# iND83213A register map
Vendor: Indiemicro; Series: Rugby; File version: 1.0
CPU: CM0 r0p1, selectable endian, no MPU, no FPU, 4 interrupt priority bits
Registers are 32-bit, read-write, no defined reset value unless marked. A register's access mark holds for its fields unless they carry their own. Offsets are from the block's base; [hi:lo] are bit positions.

## UART — UART Interface registers
Base 0x50010800; register names take the prefix UART_
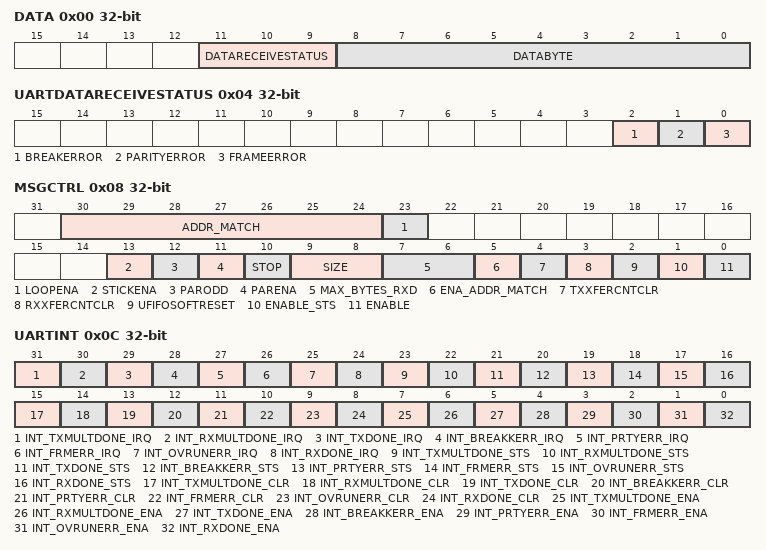
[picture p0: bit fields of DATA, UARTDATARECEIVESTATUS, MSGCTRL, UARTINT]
0x00 DATA
  [11:9] DATARECEIVESTATUS ro — Data Receive Status. Mirror for DATA_RECEIVE_STATUS: This register contains the receive status associated with the current byte read from the UART_DATA register. The Data Receive Status register is updated only after a read from the UART_DATA register. Example- Read UART_DATA byte first. Then read UART_DATA_RECEIVE_STATUS register second.
  [8:0] DATABYTE — Data. Used for both received data(ONLY bit0~7 are available) and data that is to be transmitted(bit0~8 are available): Transmit: the MSB-bit[8] is only available for Transmitter, and it indicates this data used for sending BREAK or Not 1'b1 : this DATA is used for sending BREAK; 1'b0 : this DATA is used for sending Normal Data. Receive: the MSB-bit[7] indicates the mode Match Address: 1'b0 : Normal mode, the following Rxd Datas will be received with the condition of 7bits-[6:0] matched; 1'b1 : Broadcast mode, the following Rxd Datas will be received without the condition of 7bits-[6:0] matched.
0x04 UARTDATARECEIVESTATUS — Data Receive Status
  [2] BREAKERROR ro — Break Error. This bit is set to 1 if a break condition was detected, indicating that the received data input was held LOW for longer than a full-word transmission time (defined as start, data, parity, and stop bits).
  [1] PARITYERROR ro — Parity Error. When this bit is set to 1, it indicates that the parity of the received data character does not match the parity selected as defined by bits 2 and 7 of the UARTLCR_H register.
  [0] FRAMEERROR ro — Framing Error. When this bit is set to 1, it indicates that the received byte did not have a valid stop bit (a valid stop bit is 1).
0x08 MSGCTRL — Message control
  [30:24] ADDR_MATCH — Match Address. Match Address, Only 7bit is available
  [23] LOOPENA — Loopback enable. Set to enable loopback
  [13] STICKENA — Sticky parity enable. Set to enable sticky parity
  [12] PARODD — Odd parity. 0x0: ODD Parity 0x1: EVEN parity
  [11] PARENA — Parity enable. Set to enable parity (see PARODD for odd/even)
  [10] STOP — Stop bit control. 0x0: One stop bit 0x1: If a 5-bit transmission it selects 1.5 stop bits, otherwise 2 stop bits (6, 7 & 8 bits)
  [9:8] SIZE — Transmission word size. 0x0: 5-bit(only available for Receive mode) 0x1: 6-bit(only available for Receive mode) 0x2: 7-bit(available for Receive and Transmit mode) 0x3: 8-bit(available for Receive and Transmit mode)
  [7:6] MAX_BYTES_RXD — Set Max Byte number of DATA in a rxd frame 0x0: 15-Bytes 0x1: 31-Bytes 0x2: 63-Bytes 0x3: 127-Bytes
  [5] ENA_ADDR_MATCH — Set to enable Address Match
  [4] TXXFERCNTCLR wo — TX Transfer Counter Clear. Clear TX Multi Transfer Counter to zero Autoclear: includes a synchronous reset signal which clears the register on the cycle following write.
  [3] RXXFERCNTCLR wo — RX Transfer Counter Clear. Clear RX Multi Transfer Counter to zero Autoclear: includes a synchronous reset signal which clears the register on the cycle following write.
  [2] UFIFOSOFTRESET wo — FIFO SOFT RESET. Resets FIFO pointers to zero and initializes FIFO contents to zero Autoclear: includes a synchronous reset signal which clears the register on the cycle following write.
  [1] ENABLE_STS ro — Enable status. Status of UART enable
  [0] ENABLE — Enable. Set to enable the UART
0x0C UARTINT — UART Interrupts
  [31] INT_TXMULTDONE_IRQ ro — Multiple Transmit Transactions Done Interrupt. Set by the UART when the programmed number of transmit transactions have completed. See UART_FIFO_LEVEL_CTL register.
  [30] INT_RXMULTDONE_IRQ ro — Multiple Receive Transactions Done Interrupt. Set by the UART when the programmed number of receive transactions have completed. See UART_FIFO_LEVEL_CTL register
  [29] INT_TXDONE_IRQ ro — Transmission done Interrupt. Set by the UART when the transmission is done
  [28] INT_BREAKKERR_IRQ ro — Break Error Interrupt. Set by the UART when a break error occurs
  [27] INT_PRTYERR_IRQ ro — Parity Error Interrupt. Set by the UART when a parity error occurs
  [26] INT_FRMERR_IRQ ro — Framing error Interrupt. Set by the UART when a framing error occurs
  [25] INT_OVRUNERR_IRQ ro — Overrun error Interrupt. Set by the UART when an overrun error occurs
  [24] INT_RXDONE_IRQ ro — Rx Data ready Interrupt. Set by the UART when Rx data is ready
  [23] INT_TXMULTDONE_STS ro — Multiple Transmit Transactions Done. Set by the UART when the programmed number of transmit transactions have completed. See UART_FIFO_LEVEL_CTL register.
  [22] INT_RXMULTDONE_STS ro — Multiple Receive Transactions Done. Set by the UART when the programmed number of receive transactions have completed. See UART_FIFO_LEVEL_CTL register
  [21] INT_TXDONE_STS ro — Transmission is done. Set by the UART when the transmit is done
  [20] INT_BREAKKERR_STS ro — Break IRQ. Set by the UART when a break error occurs
  [19] INT_PRTYERR_STS ro — Parity Error. Set by the UART when a parity error occurs
  [18] INT_FRMERR_STS ro — Framing error. Set by the UART when a framing error occurs
  [17] INT_OVRUNERR_STS ro — Overrun error. Set by the UART when an overrun error occurs
  [16] INT_RXDONE_STS ro — Rx Data ready. Set by the UART when Rx data is ready
  [15] INT_TXMULTDONE_CLR wo — Multiple Transmit Transactions Done Interrupt Clear. Autoclear: includes a synchronous reset signal which clears the register on the cycle following write.
  [14] INT_RXMULTDONE_CLR wo — Multiple Receive Transactions Done Interrupt Clear. Autoclear: includes a synchronous reset signal which clears the register on the cycle following write.
  [13] INT_TXDONE_CLR wo — Transmission done Interrupt Clear. Autoclear: includes a synchronous reset signal which clears the register on the cycle following write.
  [12] INT_BREAKKERR_CLR wo — Break Error Interrupt Clear. Autoclear: includes a synchronous reset signal which clears the register on the cycle following write.
  [11] INT_PRTYERR_CLR wo — Parity Error Interrupt Clear. Autoclear: includes a synchronous reset signal which clears the register on the cycle following write.
  [10] INT_FRMERR_CLR wo — Framing error Interrupt Clear. Autoclear: includes a synchronous reset signal which clears the register on the cycle following write.
  [9] INT_OVRUNERR_CLR wo — Overrun error Interrupt Clear. Autoclear: includes a synchronous reset signal which clears the register on the cycle following write.
  [8] INT_RXDONE_CLR wo — Rx Data ready Interrupt Clear. Autoclear: includes a synchronous reset signal which clears the register on the cycle following write.
  [7] INT_TXMULTDONE_ENA — Multiple Transmit Transactions Done Interrupt Enable.
  [6] INT_RXMULTDONE_ENA — Multiple Receive Transactions Done Interrupt Enable.
  [5] INT_TXDONE_ENA — Transmission done Interrupt Enable.
  [4] INT_BREAKKERR_ENA — Break Error Interrupt Enable.
  [3] INT_PRTYERR_ENA — Parity Error Interrupt Enable.
  [2] INT_FRMERR_ENA — Framing error Interrupt Enable.
  [1] INT_OVRUNERR_ENA — Overrun error Interrupt Enable.
  [0] INT_RXDONE_ENA — Rx Data ready Interrupt Enable.
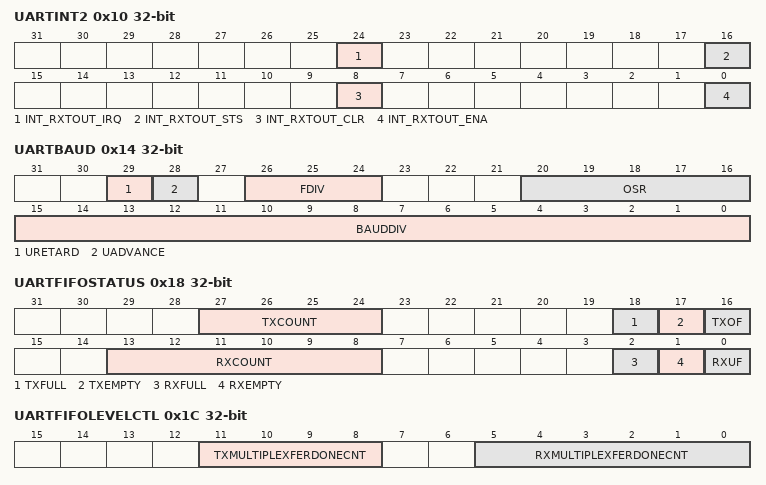
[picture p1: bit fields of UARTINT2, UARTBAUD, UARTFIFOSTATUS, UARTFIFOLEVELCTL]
0x10 UARTINT2 — Extended UART Interrupts
  [24] INT_RXTOUT_IRQ ro — Rx Time-out Interrupt. Set by the UART when RXTOUT flag is set and RXOUT interrupt is enabled.
  [16] INT_RXTOUT_STS ro — Rx Time-out. Set by the UART when timeout of 4 data frame times without reception, and data received(one or three bytes received,programmable)
  [8] INT_RXTOUT_CLR wo — Rx Time-out Interrupt Clear. Autoclear: includes a synchronous reset signal which clears the register on the cycle following write.
  [0] INT_RXTOUT_ENA — Rx Time-out Interrupt Enable.
0x14 UARTBAUD — UART Baud rate
  [29] URETARD — Retard Register. Retards the sample window by 1 cycle. For Debug.
  [28] UADVANCE — Advance Register. Advances the sample window by 1 cycle. For Debug.
  [26:24] FDIV — Fractional divider.
  [20:16] OSR — Over-sampling ratio. Valid OSR Range: 6 to 16.
  [15:0] BAUDDIV — Baud rate divider.
0x18 UARTFIFOSTATUS
  [27:24] TXCOUNT ro — Transmit FIFO current count.
  [18] TXFULL ro — Transmit FIFO full.
  [17] TXEMPTY ro — Transmit FIFO empty.
  [16] TXOF ro — Transmit FIFO overflow.
  [13:8] RXCOUNT ro — Reception FIFO current count.
  [2] RXFULL ro — Reception FIFO empty.
  [1] RXEMPTY ro — Reception FIFO empty.
  [0] RXUF ro — Reception FIFO underflow.
0x1C UARTFIFOLEVELCTL — UART FIFO Level Control
  [11:8] TXMULTIPLEXFERDONECNT — Transmit Data Count Interrupt. Number of bytes transmitted from the transmit FIFO before a INT_TX_MULTIPLE_XFER_DONE interrupt is asserted. Example: A value of 4 would be used to compare to the number of completed transfers (pops from the Tx FIFO). Valid Range: 1 to 8, NOTE: Invalid configuration value '0' will be forced to '1'
  [5:0] RXMULTIPLEXFERDONECNT — Receive Data Count Interrupt. Minimum number of bytes in the receive FIFO before a INT_RX_MULTIPLE_XFER_DONE interrupt is asserted. Example: A value of 4 would be used to compare to the number of receive transactions (pushes to the Rx FIFO). Valid Range: 1 to 32, NOTE: Invalid configuration value '0' will be forced to '1'
